# examp_regs: IP-XACT component
VLNV example.org:mylibrary:examp_regs:1.0

## Address spaces and blocks
examp_regs_mmap.examp_regs: base 'h0, range 'h2c, width 32

## Registers
Registers are 32-bit, read-only, no defined reset value unless marked. A register's access mark holds for its fields unless they carry their own. Offsets are from the block's base; lines under a group give offsets from that group; [hi:lo] are bit positions; {n}, {i} and the like mark numbered series; 'fields as' and 'values as' point back to an identical list; <NAME> marks a mode.

## examp_regs_mmap.examp_regs — Example register description.
Base 0x00000000
0x00 common group — These registers should be instantiated at the base address of an fpga.
  0x00 scratchpad rw reset 0x12345678 — Scratchpad register for testing.
  0x04 id — Read-only ID register. This is a unique identification number for this fpga design.
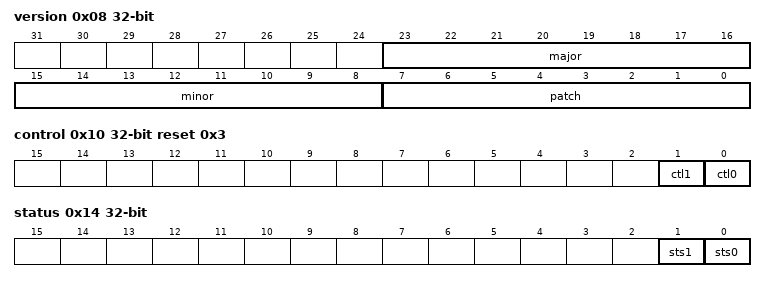
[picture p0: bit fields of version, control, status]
  0x08 version — Read-only version register. Semantic versioning is used. In short: MAJOR version = incompatible API change; MINOR version = new functionality added in a backward compatible manner; PATCH version = backward compatible bug fix; For more information, see https://semver.org
    [23:16] major, [15:8] minor, [7:0] patch
  0x0C git — The 8 left-most characters of the git commit hash for this fpga design.
0x10 control rw reset 0x3 — Overall control register.
  [1] ctl1, [0] ctl0
0x14 status — Overall status register.
  [1] sts1 — Status 1
  [0] sts0 — Status 0
0x18 hwrw rw reset 0xA — SW and HW can write, we flag needed to trigger write from hw. Also include outputs for swacc (rd / wr) and swmod (wr)
  [31:0] data
{0x1C+4i} wr_pulse[{i}] (i=0..1) wo reset 0x0 — Write pulse register. Just a write pulse.
  [0] data
{0x24+4i} cntr[{i}] (i=0..1) reset 0x0 — Counter register. Just a simple up counter
  [15:0] cnt
